# CH585SFR register map
Vendor: WCH Ltd.; Series: CH58x; File version: 1.0
CPU: RISC-V r0p0, little endian, no MPU, no FPU, 2 interrupt priority bits
Registers are 8-bit, Read or Write, reset 0x0 unless marked. A register's access mark holds for its fields unless they carry their own. Offsets are from the block's base; [hi:lo] are bit positions.

## TMR0 — Timer0 register
Base 0x40002000
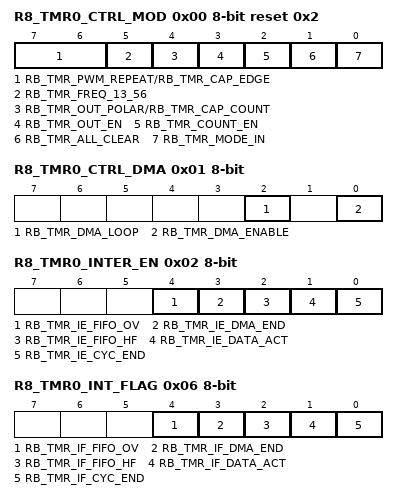
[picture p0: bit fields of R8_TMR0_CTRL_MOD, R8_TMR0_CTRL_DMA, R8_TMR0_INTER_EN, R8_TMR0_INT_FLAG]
0x00 R8_TMR0_CTRL_MOD reset 0x2 — RW, TMR0 mode control
  [7:6] RB_TMR_PWM_REPEAT/RB_TMR_CAP_EDGE — RW, timer PWM repeat mode: 00=1, 01=4, 10=8, 11-16;RW, timer capture edge mode: 00=disable, 01=edge change, 10=fall to fall, 11-rise to rise
  [5] RB_TMR_FREQ_13_56 — RW,Counting frequency setting bits for TMR0 and TMR3
  [4] RB_TMR_OUT_POLAR/RB_TMR_CAP_COUNT — RW, timer PWM output polarity: 0=default low and high action, 1=default high and low action;RW, count sub-mode if RB_TMR_MODE_IN=1: 0=capture, 1=count
  [3] RB_TMR_OUT_EN — RW, timer output enable
  [2] RB_TMR_COUNT_EN — RW, timer count enable
  [1] RB_TMR_ALL_CLEAR — RW, force clear timer FIFO and count
  [0] RB_TMR_MODE_IN — RW, timer in mode: 0=timer/PWM, 1=capture/count
0x01 R8_TMR0_CTRL_DMA — RO/WO, DMA control register
  [2] RB_TMR_DMA_LOOP — RW, Enable bit for DMA address loop function
  [0] RB_TMR_DMA_ENABLE — RW, DMA function enable bit
0x02 R8_TMR0_INTER_EN — RW, TMR0 interrupt enable
  [4] RB_TMR_IE_FIFO_OV — RW, enable interrupt for timer FIFO overflow
  [3] RB_TMR_IE_DMA_END — RW, enable interrupt for timer1/2 DMA completion
  [2] RB_TMR_IE_FIFO_HF — RW, enable interrupt for timer FIFO half (capture fifo >=4 or PWM fifo less than 3)
  [1] RB_TMR_IE_DATA_ACT — RW, enable interrupt for timer capture input action or PWM trigger
  [0] RB_TMR_IE_CYC_END — RW, enable interrupt for timer capture count timeout or PWM cycle end
0x06 R8_TMR0_INT_FLAG Read / Write 1 to Clear — RW1, TMR0 interrupt flag
  [4] RB_TMR_IF_FIFO_OV — RW1, interrupt flag for timer FIFO overflow
  [3] RB_TMR_IF_DMA_END — RW1, interrupt flag for timer1/2 DMA completion
  [2] RB_TMR_IF_FIFO_HF — RW1, interrupt flag for timer FIFO half (capture fifo >=4 or PWM fifo less than 3
  [1] RB_TMR_IF_DATA_ACT — RW1, interrupt flag for timer capture input action or PWM trigger
  [0] RB_TMR_IF_CYC_END — RW1, interrupt flag for timer capture count timeout or PWM cycle end
0x07 R8_TMR0_FIFO_COUNT ro reset not defined — RO, TMR0 FIFO count status
  [3:0] R8_TMR0_FIFO_COUNT — R0,TMR0 FIFO count status
0x08 R32_TMR0_COUNT 32-bit ro reset not defined — RO, TMR0 current count
  [25:0] R32_TMR0_COUNT — RW1,TMR0 current count
0x0C R32_TMR0_CNT_END 32-bit reset not defined — RW, TMR0 end count value, only low 26 bit
  [31:0] R32_TMR0_CNT_END — RW1,TMR0 end count value
0x10 R32_TMR0_FIFO 32-bit ro reset not defined — RO/WO, TMR0 FIFO register, only low 26 bit
  [31:0] R32_TMR0_FIFO — RW1,TMR0 FIFO register
0x14 R32_TMR0_DMA_NOW 32-bit ro reset not defined — RO, DMA current buffer address
  [16:2] RB_TMR0_DMA_NOW — RW, DMA data buffer current address
0x18 R32_TMR0_DMA_BEG 32-bit reset not defined — RW, DMA start buffer address
  [16:2] RB_TMR0_DMA_BEG — RW, The starting address of the DMA data buffer must be aligned with 4 bytes
0x1C R32_TMR0_DMA_END 32-bit reset not defined — RW, DMA end buffer address
  [16:2] RB_TMR0_DMA_END — RW, DMA data buffer end address (excluding), the address must be aligned with 4 bytes

## TMR1 — Timer1 register
Base 0x40002400
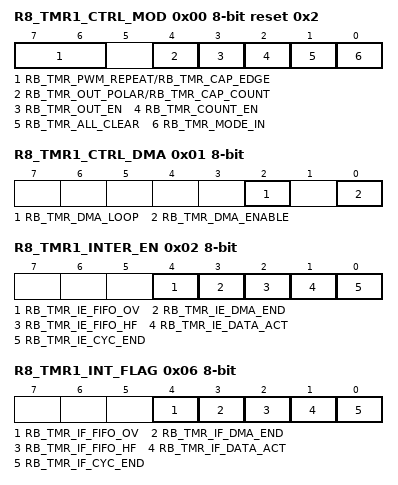
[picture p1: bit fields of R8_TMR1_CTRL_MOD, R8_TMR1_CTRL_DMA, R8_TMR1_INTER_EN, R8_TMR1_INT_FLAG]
0x00 R8_TMR1_CTRL_MOD reset 0x2 — RW, TMR1 mode control
  [7:6] RB_TMR_PWM_REPEAT/RB_TMR_CAP_EDGE — RW, timer PWM repeat mode: 00=1, 01=4, 10=8, 11-16;RW, timer capture edge mode: 00=disable, 01=edge change, 10=fall to fall, 11-rise to rise
  [4] RB_TMR_OUT_POLAR/RB_TMR_CAP_COUNT — RW, timer PWM output polarity: 0=default low and high action, 1=default high and low action;RW, count sub-mode if RB_TMR_MODE_IN=1: 0=capture, 1=count
  [3] RB_TMR_OUT_EN — RW, timer output enable
  [2] RB_TMR_COUNT_EN — RW, timer count enable
  [1] RB_TMR_ALL_CLEAR — RW, force clear timer FIFO and count
  [0] RB_TMR_MODE_IN — RW, timer in mode: 0=timer/PWM, 1=capture/count
0x01 R8_TMR1_CTRL_DMA — RW, TMR1 DMA control
  [2] RB_TMR_DMA_LOOP — RW, timer1 DMA address loop enable
  [0] RB_TMR_DMA_ENABLE — RW, timer1 DMA enable
0x02 R8_TMR1_INTER_EN — RW, TMR1 interrupt enable
  [4] RB_TMR_IE_FIFO_OV — RW, enable interrupt for timer FIFO overflow
  [3] RB_TMR_IE_DMA_END — RW, enable interrupt for timer1 DMA completion
  [2] RB_TMR_IE_FIFO_HF — RW, enable interrupt for timer FIFO half (capture fifo >=4 or PWM fifo less than 3)
  [1] RB_TMR_IE_DATA_ACT — RW, enable interrupt for timer capture input action or PWM trigger
  [0] RB_TMR_IE_CYC_END — RW, enable interrupt for timer capture count timeout or PWM cycle end
0x06 R8_TMR1_INT_FLAG Read or Write 1 to Clear — RW1, TMR1 interrupt flag
  [4] RB_TMR_IF_FIFO_OV — RW1, interrupt flag for timer FIFO overflow
  [3] RB_TMR_IF_DMA_END — RW1, interrupt flag for timer1 DMA completion
  [2] RB_TMR_IF_FIFO_HF — RW1, interrupt flag for timer FIFO half (capture fifo >=4 or PWM fifo less than 3
  [1] RB_TMR_IF_DATA_ACT — RW1, interrupt flag for timer capture input action or PWM trigger
  [0] RB_TMR_IF_CYC_END — RW1, interrupt flag for timer capture count timeout or PWM cycle end
0x07 R8_TMR1_FIFO_COUNT ro reset not defined — RO, TMR1 FIFO count status
  [3:0] R8_TMR1_FIFO_COUNT — RW1, TMR1 FIFO count status
0x08 R32_TMR1_COUNT 32-bit ro reset not defined — RO, TMR1 current count
  [25:0] R32_TMR1_COUNT — RW1,TMR1 current count
0x0C R32_TMR1_CNT_END 32-bit reset not defined — RW, TMR1 end count value, only low 26 bit
  [31:0] R32_TMR1_CNT_END — RW1,TMR1 end count value,
0x10 R32_TMR1_FIFO 32-bit ro reset not defined — RO, TMR1 FIFO register, only low 26 bit
  [31:0] R32_TMR1_FIFO — RW1,TMR1 FIFO register
0x14 R16_TMR1_DMA_NOW 16-bit ro reset not defined — RO, TMR1 DMA current address
  [16:2] R16_TMR1_DMA_NOW — RO,DMA data buffer current address
0x18 R16_TMR1_DMA_BEG 16-bit reset not defined — RW, TMR1 DMA begin address
  [16:2] R16_TMR1_DMA_BEG — RW,TMR1 DMA data buffer start address
0x1C R16_TMR1_DMA_END 16-bit reset not defined — RW, TMR1 DMA end address
  [16:2] R16_TMR1_DMA_END — RW,DMA data buffer end address
